VERSION ""

NS_ :

BS_:

BU_: ADTF
VAL_TABLE_ IEBM_State 15 "IEBM_STATE_ERROR" 2 "IEBM_STATE_EMERGENCY_BRAKING" 1 "IEBM_STATE_UPDATING" 0 "IEBM_STATE_STANDBY" ;
VAL_TABLE_ obst_types_to_be_considered 7 "THAS_ALL_OBSTACLES" 6 "THAS_DYNAMIC_AND_PEDESTRIANS" 5 "THAS_ONLY_PEDESTRIANS" 4 "THAS_ONLY_PEDESTRIANS" 3 "THAS_STATIC_AND_DYNAMIC," 2 "THAS_ONLY_DYNAMIC" 1 "THAS_ONLY_STATIC" 0 "default" ;

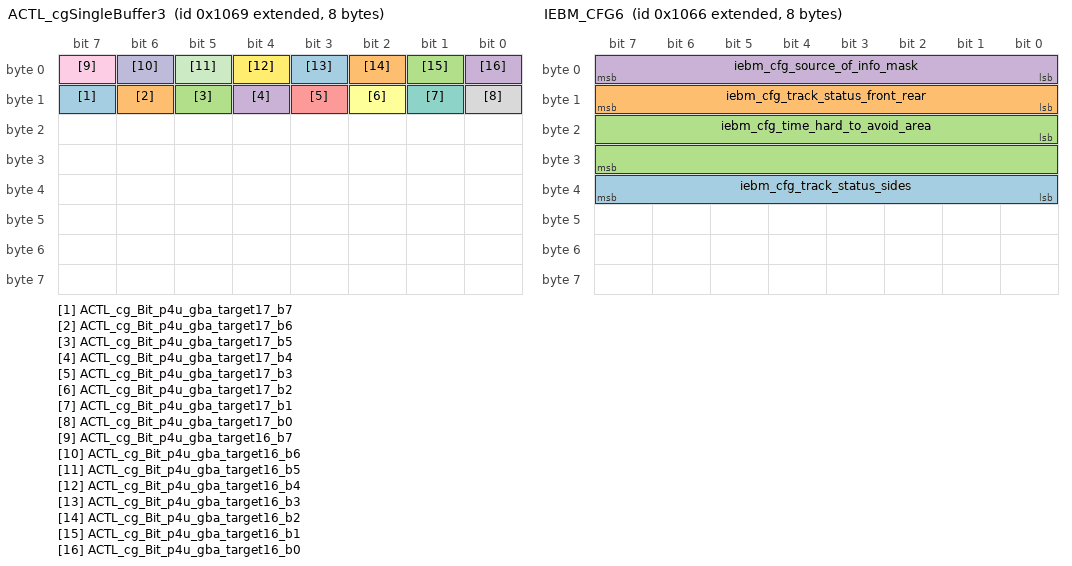
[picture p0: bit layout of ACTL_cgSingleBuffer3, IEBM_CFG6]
BO_ 2147487849 ACTL_cgSingleBuffer3: 8 ADTF
 SG_ ACTL_cg_Bit_p4u_gba_target17_b7 : 15|1@1+ (1,0) [0|0] "" Vector__XXX
 SG_ ACTL_cg_Bit_p4u_gba_target17_b6 : 14|1@1+ (1,0) [0|0] "" Vector__XXX
 SG_ ACTL_cg_Bit_p4u_gba_target17_b5 : 13|1@1+ (1,0) [0|0] "" Vector__XXX
 SG_ ACTL_cg_Bit_p4u_gba_target17_b4 : 12|1@1+ (1,0) [0|0] "" Vector__XXX
 SG_ ACTL_cg_Bit_p4u_gba_target17_b3 : 11|1@1+ (1,0) [0|0] "" Vector__XXX
 SG_ ACTL_cg_Bit_p4u_gba_target17_b2 : 10|1@1+ (1,0) [0|0] "" Vector__XXX
 SG_ ACTL_cg_Bit_p4u_gba_target17_b1 : 9|1@1+ (1,0) [0|0] "" Vector__XXX
 SG_ ACTL_cg_Bit_p4u_gba_target17_b0 : 8|1@1+ (1,0) [0|0] "" Vector__XXX
 SG_ ACTL_cg_Bit_p4u_gba_target16_b7 : 7|1@1+ (1,0) [0|0] "" Vector__XXX
 SG_ ACTL_cg_Bit_p4u_gba_target16_b6 : 6|1@1+ (1,0) [0|0] "" Vector__XXX
 SG_ ACTL_cg_Bit_p4u_gba_target16_b5 : 5|1@1+ (1,0) [0|0] "" Vector__XXX
 SG_ ACTL_cg_Bit_p4u_gba_target16_b4 : 4|1@1+ (1,0) [0|0] "" Vector__XXX
 SG_ ACTL_cg_Bit_p4u_gba_target16_b3 : 3|1@1+ (1,0) [0|0] "" Vector__XXX
 SG_ ACTL_cg_Bit_p4u_gba_target16_b2 : 2|1@1+ (1,0) [0|0] "" Vector__XXX
 SG_ ACTL_cg_Bit_p4u_gba_target16_b1 : 1|1@1+ (1,0) [0|0] "" Vector__XXX
 SG_ ACTL_cg_Bit_p4u_gba_target16_b0 : 0|1@1+ (1,0) [0|0] "" Vector__XXX

BO_ 2147487848 ACTL_cgSingleBuffer2: 8 ADTF
 SG_ ACTL_cg_Bit_p4u_gba_target15_b7 : 63|1@1+ (1,0) [0|0] "" Vector__XXX
 SG_ ACTL_cg_Bit_p4u_gba_target15_b6 : 62|1@1+ (1,0) [0|0] "" Vector__XXX
 SG_ ACTL_cg_Bit_p4u_gba_target15_b5 : 61|1@1+ (1,0) [0|0] "" Vector__XXX
 SG_ ACTL_cg_Bit_p4u_gba_target15_b4 : 60|1@1+ (1,0) [0|0] "" Vector__XXX
 SG_ ACTL_cg_Bit_p4u_gba_target15_b3 : 59|1@1+ (1,0) [0|0] "" Vector__XXX
 SG_ ACTL_cg_Bit_p4u_gba_target15_b2 : 58|1@1+ (1,0) [0|0] "" Vector__XXX
 SG_ ACTL_cg_Bit_p4u_gba_target15_b1 : 57|1@1+ (1,0) [0|0] "" Vector__XXX
 SG_ ACTL_cg_Bit_p4u_gba_target15_b0 : 56|1@1+ (1,0) [0|0] "" Vector__XXX
 SG_ ACTL_cg_Bit_p4u_gba_target14_b7 : 55|1@1+ (1,0) [0|0] "" Vector__XXX
 SG_ ACTL_cg_Bit_p4u_gba_target14_b6 : 54|1@1+ (1,0) [0|0] "" Vector__XXX
 SG_ ACTL_cg_Bit_p4u_gba_target14_b5 : 53|1@1+ (1,0) [0|0] "" Vector__XXX
 SG_ ACTL_cg_Bit_p4u_gba_target14_b4 : 52|1@1+ (1,0) [0|0] "" Vector__XXX
 SG_ ACTL_cg_Bit_p4u_gba_target14_b3 : 51|1@1+ (1,0) [0|0] "" Vector__XXX
 SG_ ACTL_cg_Bit_p4u_gba_target14_b2 : 50|1@1+ (1,0) [0|0] "" Vector__XXX
 SG_ ACTL_cg_Bit_p4u_gba_target14_b1 : 49|1@1+ (1,0) [0|0] "" Vector__XXX
 SG_ ACTL_cg_Bit_p4u_gba_target14_b0 : 48|1@1+ (1,0) [0|0] "" Vector__XXX
 SG_ ACTL_cg_Bit_p4u_gba_target13_b7 : 47|1@1+ (1,0) [0|0] "" Vector__XXX
 SG_ ACTL_cg_Bit_p4u_gba_target13_b6 : 46|1@1+ (1,0) [0|0] "" Vector__XXX
 SG_ ACTL_cg_Bit_p4u_gba_target13_b5 : 45|1@1+ (1,0) [0|0] "" Vector__XXX
 SG_ ACTL_cg_Bit_p4u_gba_target13_b4 : 44|1@1+ (1,0) [0|0] "" Vector__XXX
 SG_ ACTL_cg_Bit_p4u_gba_target13_b3 : 43|1@1+ (1,0) [0|0] "" Vector__XXX
 SG_ ACTL_cg_Bit_p4u_gba_target13_b2 : 42|1@1+ (1,0) [0|0] "" Vector__XXX
 SG_ ACTL_cg_Bit_p4u_gba_target13_b1 : 41|1@1+ (1,0) [0|0] "" Vector__XXX
 SG_ ACTL_cg_Bit_p4u_gba_target13_b0 : 40|1@1+ (1,0) [0|0] "" Vector__XXX
 SG_ ACTL_cg_Bit_p4u_gba_target12_b7 : 39|1@1+ (1,0) [0|0] "" Vector__XXX
 SG_ ACTL_cg_Bit_p4u_gba_target12_b6 : 38|1@1+ (1,0) [0|0] "" Vector__XXX
 SG_ ACTL_cg_Bit_p4u_gba_target12_b5 : 37|1@1+ (1,0) [0|0] "" Vector__XXX
 SG_ ACTL_cg_Bit_p4u_gba_target12_b4 : 36|1@1+ (1,0) [0|0] "" Vector__XXX
 SG_ ACTL_cg_Bit_p4u_gba_target12_b3 : 35|1@1+ (1,0) [0|0] "" Vector__XXX
 SG_ ACTL_cg_Bit_p4u_gba_target12_b2 : 34|1@1+ (1,0) [0|0] "" Vector__XXX
 SG_ ACTL_cg_Bit_p4u_gba_target12_b1 : 33|1@1+ (1,0) [0|0] "" Vector__XXX
 SG_ ACTL_cg_Bit_p4u_gba_target12_b0 : 32|1@1+ (1,0) [0|0] "" Vector__XXX
 SG_ ACTL_cg_Bit_p4u_gba_target11_b7 : 31|1@1+ (1,0) [0|0] "" Vector__XXX
 SG_ ACTL_cg_Bit_p4u_gba_target11_b6 : 30|1@1+ (1,0) [0|0] "" Vector__XXX
 SG_ ACTL_cg_Bit_p4u_gba_target11_b5 : 29|1@1+ (1,0) [0|0] "" Vector__XXX
 SG_ ACTL_cg_Bit_p4u_gba_target11_b4 : 28|1@1+ (1,0) [0|0] "" Vector__XXX
 SG_ ACTL_cg_Bit_p4u_gba_target11_b3 : 27|1@1+ (1,0) [0|0] "" Vector__XXX
 SG_ ACTL_cg_Bit_p4u_gba_target11_b2 : 26|1@1+ (1,0) [0|1] "" Vector__XXX
 SG_ ACTL_cg_Bit_p4u_gba_target11_b1 : 25|1@1+ (1,0) [0|0] "" Vector__XXX
 SG_ ACTL_cg_Bit_p4u_gba_target11_b0 : 24|1@1+ (1,0) [0|0] "" Vector__XXX
 SG_ ACTL_cg_Bit_p4u_gba_target10_b7 : 23|1@1+ (1,0) [0|0] "" Vector__XXX
 SG_ ACTL_cg_Bit_p4u_gba_target10_b6 : 22|1@1+ (1,0) [0|0] "" Vector__XXX
 SG_ ACTL_cg_Bit_p4u_gba_target10_b5 : 21|1@1+ (1,0) [0|0] "" Vector__XXX
 SG_ ACTL_cg_Bit_p4u_gba_target10_b4 : 20|1@1+ (1,0) [0|0] "" Vector__XXX
 SG_ ACTL_cg_Bit_p4u_gba_target10_b3 : 19|1@1+ (1,0) [0|0] "" Vector__XXX
 SG_ ACTL_cg_Bit_p4u_gba_target10_b2 : 18|1@1+ (1,0) [0|0] "" Vector__XXX
 SG_ ACTL_cg_Bit_p4u_gba_target10_b1 : 17|1@1+ (1,0) [0|0] "" Vector__XXX
 SG_ ACTL_cg_Bit_p4u_gba_target10_b0 : 16|1@1+ (1,0) [0|0] "" Vector__XXX
 SG_ ACTL_cg_Bit_p4u_gba_target9_b7 : 15|1@1+ (1,0) [0|0] "" Vector__XXX
 SG_ ACTL_cg_Bit_p4u_gba_target9_b6 : 14|1@1+ (1,0) [0|0] "" Vector__XXX
 SG_ ACTL_cg_Bit_p4u_gba_target9_b5 : 13|1@1+ (1,0) [0|0] "" Vector__XXX
 SG_ ACTL_cg_Bit_p4u_gba_target9_b4 : 12|1@1+ (1,0) [0|0] "" Vector__XXX
 SG_ ACTL_cg_Bit_p4u_gba_target9_b3 : 11|1@1+ (1,0) [0|0] "" Vector__XXX
 SG_ ACTL_cg_Bit_p4u_gba_target9_b2 : 10|1@1+ (1,0) [0|0] "" Vector__XXX
 SG_ ACTL_cg_Bit_p4u_gba_target9_b1 : 9|1@1+ (1,0) [0|0] "" Vector__XXX
 SG_ ACTL_cg_Bit_p4u_gba_target9_b0 : 8|1@1+ (1,0) [0|0] "" Vector__XXX
 SG_ ACTL_cg_Bit_p4u_gba_target8_b7 : 7|1@1+ (1,0) [0|0] "" Vector__XXX
 SG_ ACTL_cg_Bit_p4u_gba_target8_b6 : 6|1@1+ (1,0) [0|0] "" Vector__XXX
 SG_ ACTL_cg_Bit_p4u_gba_target8_b5 : 5|1@1+ (1,0) [0|0] "" Vector__XXX
 SG_ ACTL_cg_Bit_p4u_gba_target8_b4 : 4|1@1+ (1,0) [0|0] "" Vector__XXX
 SG_ ACTL_cg_Bit_p4u_gba_target8_b3 : 3|1@1+ (1,0) [0|0] "" Vector__XXX
 SG_ ACTL_cg_Bit_p4u_gba_target8_b2 : 2|1@1+ (1,0) [0|0] "" Vector__XXX
 SG_ ACTL_cg_Bit_p4u_gba_target8_b1 : 1|1@1+ (1,0) [0|0] "" Vector__XXX
 SG_ ACTL_cg_Bit_p4u_gba_target8_b0 : 0|1@1+ (1,0) [0|0] "" Vector__XXX

BO_ 2147487847 ACTL_cgSingleBuffer1: 8 ADTF
 SG_ ACTL_cg_Bit_p4u_gba_target7_b7 : 63|1@1+ (1,0) [0|0] "" Vector__XXX
 SG_ ACTL_cg_Bit_p4u_gba_target7_b6 : 62|1@1+ (1,0) [0|0] "" Vector__XXX
 SG_ ACTL_cg_Bit_p4u_gba_target7_b5 : 61|1@1+ (1,0) [0|0] "" Vector__XXX
 SG_ ACTL_cg_Bit_p4u_gba_target7_b4 : 60|1@1+ (1,0) [0|0] "" Vector__XXX
 SG_ ACTL_cg_Bit_p4u_gba_target7_b3 : 59|1@1+ (1,0) [0|0] "" Vector__XXX
 SG_ ACTL_cg_Bit_p4u_gba_target7_b2 : 58|1@1+ (1,0) [0|0] "" Vector__XXX
 SG_ ACTL_cg_Bit_p4u_gba_target7_b1 : 57|1@1+ (1,0) [0|0] "" Vector__XXX
 SG_ ACTL_cg_Bit_p4u_gba_target7_b0 : 56|1@1+ (1,0) [0|0] "" Vector__XXX
 SG_ ACTL_cg_Bit_p4u_gba_target6_b7 : 55|1@1+ (1,0) [0|0] "" Vector__XXX
 SG_ ACTL_cg_Bit_p4u_gba_target6_b6 : 54|1@1+ (1,0) [0|0] "" Vector__XXX
 SG_ ACTL_cg_Bit_p4u_gba_target6_b5 : 53|1@1+ (1,0) [0|0] "" Vector__XXX
 SG_ ACTL_cg_Bit_p4u_gba_target6_b4 : 52|1@1+ (1,0) [0|0] "" Vector__XXX
 SG_ ACTL_cg_Bit_p4u_gba_target6_b3 : 51|1@1+ (1,0) [0|0] "" Vector__XXX
 SG_ ACTL_cg_Bit_p4u_gba_target6_b2 : 50|1@1+ (1,0) [0|0] "" Vector__XXX
 SG_ ACTL_cg_Bit_p4u_gba_target6_b1 : 49|1@1+ (1,0) [0|0] "" Vector__XXX
 SG_ ACTL_cg_Bit_p4u_gba_target6_b0 : 48|1@1+ (1,0) [0|0] "" Vector__XXX
 SG_ ACTL_cg_Bit_p4u_gba_target5_b7 : 47|1@1+ (1,0) [0|0] "" Vector__XXX
 SG_ ACTL_cg_Bit_p4u_gba_target5_b6 : 46|1@1+ (1,0) [0|0] "" Vector__XXX
 SG_ ACTL_cg_Bit_p4u_gba_target5_b5 : 45|1@1+ (1,0) [0|0] "" Vector__XXX
 SG_ ACTL_cg_Bit_p4u_gba_target5_b4 : 44|1@1+ (1,0) [0|0] "" Vector__XXX
 SG_ ACTL_cg_Bit_p4u_gba_target5_b3 : 43|1@1+ (1,0) [0|0] "" Vector__XXX
 SG_ ACTL_cg_Bit_p4u_gba_target5_b2 : 42|1@1+ (1,0) [0|0] "" Vector__XXX
 SG_ ACTL_cg_Bit_p4u_gba_target5_b1 : 41|1@1+ (1,0) [0|0] "" Vector__XXX
 SG_ ACTL_cg_Bit_p4u_gba_target5_b0 : 40|1@1+ (1,0) [0|0] "" Vector__XXX
 SG_ ACTL_cg_Bit_p4u_gba_target4_b7 : 39|1@1+ (1,0) [0|0] "" Vector__XXX
 SG_ ACTL_cg_Bit_p4u_gba_target4_b6 : 38|1@1+ (1,0) [0|0] "" Vector__XXX
 SG_ ACTL_cg_Bit_p4u_gba_target4_b5 : 37|1@1+ (1,0) [0|0] "" Vector__XXX
 SG_ ACTL_cg_Bit_p4u_gba_target4_b4 : 36|1@1+ (1,0) [0|0] "" Vector__XXX
 SG_ ACTL_cg_Bit_p4u_gba_target4_b3 : 35|1@1+ (1,0) [0|0] "" Vector__XXX
 SG_ ACTL_cg_Bit_p4u_gba_target4_b2 : 34|1@1+ (1,0) [0|0] "" Vector__XXX
 SG_ ACTL_cg_Bit_p4u_gba_target4_b1 : 33|1@1+ (1,0) [0|0] "" Vector__XXX
 SG_ ACTL_cg_Bit_p4u_gba_target4_b0 : 32|1@1+ (1,0) [0|0] "" Vector__XXX
 SG_ ACTL_cg_Bit_p4u_gba_target3_b7 : 31|1@1+ (1,0) [0|0] "" Vector__XXX
 SG_ ACTL_cg_Bit_p4u_gba_target3_b6 : 30|1@1+ (1,0) [0|0] "" Vector__XXX
 SG_ ACTL_cg_Bit_p4u_gba_target3_b5 : 29|1@1+ (1,0) [0|0] "" Vector__XXX
 SG_ ACTL_cg_Bit_p4u_gba_target3_b4 : 28|1@1+ (1,0) [0|0] "" Vector__XXX
 SG_ ACTL_cg_Bit_p4u_gba_target3_b3 : 27|1@1+ (1,0) [0|0] "" Vector__XXX
 SG_ ACTL_cg_Bit_p4u_gba_target3_b2 : 26|1@1+ (1,0) [0|0] "" Vector__XXX
 SG_ ACTL_cg_Bit_p4u_gba_target3_b1 : 25|1@1+ (1,0) [0|0] "" Vector__XXX
 SG_ ACTL_cg_Bit_p4u_gba_target3_b0 : 24|1@1+ (1,0) [0|0] "" Vector__XXX
 SG_ ACTL_cg_Bit_p4u_gba_target2_b7 : 23|1@1+ (1,0) [0|0] "" Vector__XXX
 SG_ ACTL_cg_Bit_p4u_gba_target2_b6 : 22|1@1+ (1,0) [0|0] "" Vector__XXX
 SG_ ACTL_cg_Bit_p4u_gba_target2_b5 : 21|1@1+ (1,0) [0|0] "" Vector__XXX
 SG_ ACTL_cg_Bit_p4u_gba_target2_b4 : 20|1@1+ (1,0) [0|0] "" Vector__XXX
 SG_ ACTL_cg_Bit_p4u_gba_target2_b3 : 19|1@1+ (1,0) [0|0] "" Vector__XXX
 SG_ ACTL_cg_Bit_p4u_gba_target2_b2 : 18|1@1+ (1,0) [0|0] "" Vector__XXX
 SG_ ACTL_cg_Bit_p4u_gba_target2_b1 : 17|1@1+ (1,0) [0|0] "" Vector__XXX
 SG_ ACTL_cg_Bit_p4u_gba_target2_b0 : 16|1@1+ (1,0) [0|0] "" Vector__XXX
 SG_ ACTL_cg_Bit_p4u_gba_target1_b7 : 15|1@1+ (1,0) [0|0] "" Vector__XXX
 SG_ ACTL_cg_Bit_p4u_gba_target1_b6 : 14|1@1+ (1,0) [0|0] "" Vector__XXX
 SG_ ACTL_cg_Bit_p4u_gba_target1_b5 : 13|1@1+ (1,0) [0|0] "" Vector__XXX
 SG_ ACTL_cg_Bit_p4u_gba_target1_b4 : 12|1@1+ (1,0) [0|0] "" Vector__XXX
 SG_ ACTL_cg_Bit_p4u_gba_target1_b3 : 11|1@1+ (1,0) [0|0] "" Vector__XXX
 SG_ ACTL_cg_Bit_p4u_gba_target1_b2 : 10|1@1+ (1,0) [0|0] "" Vector__XXX
 SG_ ACTL_cg_Bit_p4u_gba_target1_b1 : 9|1@1+ (1,0) [0|0] "" Vector__XXX
 SG_ ACTL_cg_Bit_p4u_gba_target1_b0 : 8|1@1+ (1,0) [0|0] "" Vector__XXX
 SG_ ACTL_cg_Bit_p4u_gba_target_b7 : 7|1@1+ (1,0) [0|0] "" Vector__XXX
 SG_ ACTL_cg_Bit_p4u_gba_target_b6 : 6|1@1+ (1,0) [0|0] "" Vector__XXX
 SG_ ACTL_cg_Bit_p4u_gba_target_b5 : 5|1@1+ (1,0) [0|0] "" Vector__XXX
 SG_ ACTL_cg_Bit_p4u_gba_target_b4 : 4|1@1+ (1,0) [0|0] "" Vector__XXX
 SG_ ACTL_cg_Bit_p4u_gba_target_b3 : 3|1@1+ (1,0) [0|0] "" Vector__XXX
 SG_ ACTL_cg_Bit_p4u_gba_target_b2 : 2|1@1+ (1,0) [0|0] "" Vector__XXX
 SG_ ACTL_cg_Bit_p4u_gba_target_b1 : 1|1@1+ (1,0) [0|0] "" Vector__XXX
 SG_ ACTL_cg_Bit_p4u_gba_target_b0 : 0|1@1+ (1,0) [0|0] "" Vector__XXX

BO_ 2147487846 IEBM_CFG6: 8 ADTF
 SG_ iebm_cfg_track_status_sides : 32|8@1+ (1,0) [0|0] "" Vector__XXX
 SG_ iebm_cfg_track_status_front_rear : 8|8@1+ (1,0) [0|0] "" Vector__XXX
 SG_ iebm_cfg_time_hard_to_avoid_area : 16|16@1+ (1,0) [0|0] "" Vector__XXX
 SG_ iebm_cfg_source_of_info_mask : 0|8@1+ (1,0) [0|0] "" Vector__XXX

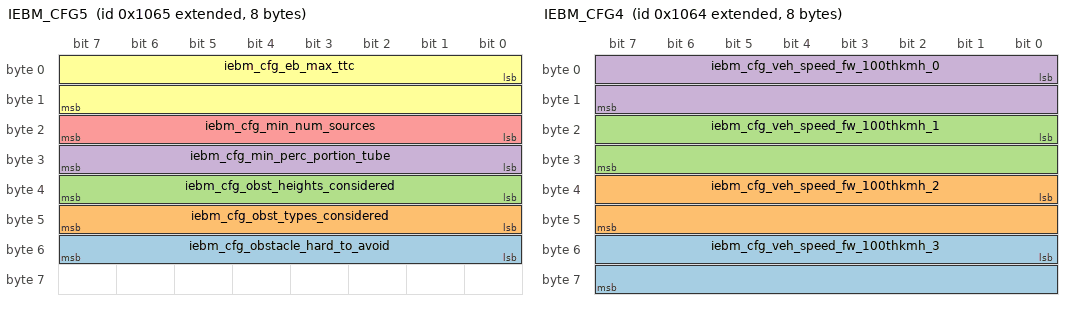
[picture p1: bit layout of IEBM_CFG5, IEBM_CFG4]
BO_ 2147487845 IEBM_CFG5: 8 ADTF
 SG_ iebm_cfg_obstacle_hard_to_avoid : 48|8@1+ (1,0) [0|0] "" Vector__XXX
 SG_ iebm_cfg_obst_types_considered : 40|8@1+ (1,0) [0|0] "" Vector__XXX
 SG_ iebm_cfg_obst_heights_considered : 32|8@1+ (1,0) [0|0] "" Vector__XXX
 SG_ iebm_cfg_min_perc_portion_tube : 24|8@1+ (1,0) [0|0] "" Vector__XXX
 SG_ iebm_cfg_min_num_sources : 16|8@1+ (1,0) [0|0] "" Vector__XXX
 SG_ iebm_cfg_eb_max_ttc : 0|16@1+ (1,0) [0|0] "" Vector__XXX

BO_ 2147487844 IEBM_CFG4: 8 ADTF
 SG_ iebm_cfg_veh_speed_fw_100thkmh_3 : 48|16@1+ (1,0) [0|0] "" Vector__XXX
 SG_ iebm_cfg_veh_speed_fw_100thkmh_2 : 32|16@1+ (1,0) [0|0] "" Vector__XXX
 SG_ iebm_cfg_veh_speed_fw_100thkmh_1 : 16|16@1+ (1,0) [0|0] "" Vector__XXX
 SG_ iebm_cfg_veh_speed_fw_100thkmh_0 : 0|16@1+ (1,0) [0|0] "" Vector__XXX

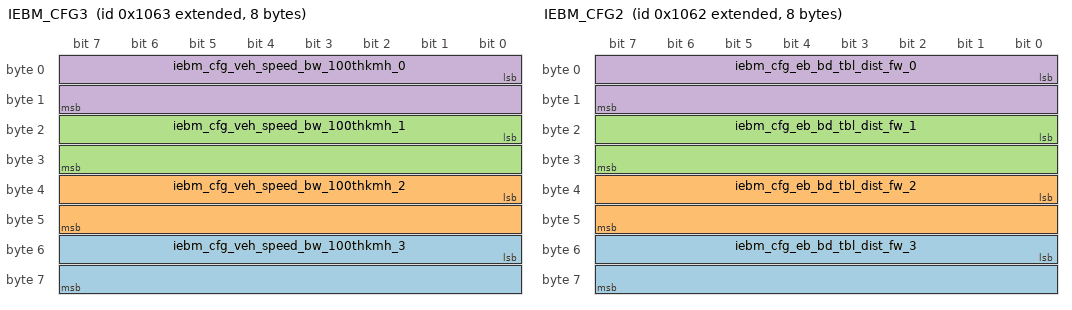
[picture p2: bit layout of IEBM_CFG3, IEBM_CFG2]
BO_ 2147487843 IEBM_CFG3: 8 ADTF
 SG_ iebm_cfg_veh_speed_bw_100thkmh_3 : 48|16@1+ (1,0) [0|0] "" Vector__XXX
 SG_ iebm_cfg_veh_speed_bw_100thkmh_2 : 32|16@1+ (1,0) [0|0] "" Vector__XXX
 SG_ iebm_cfg_veh_speed_bw_100thkmh_1 : 16|16@1+ (1,0) [0|0] "" Vector__XXX
 SG_ iebm_cfg_veh_speed_bw_100thkmh_0 : 0|16@1+ (1,0) [0|0] "" Vector__XXX

BO_ 2147487842 IEBM_CFG2: 8 ADTF
 SG_ iebm_cfg_eb_bd_tbl_dist_fw_3 : 48|16@1- (1,0) [0|0] "" Vector__XXX
 SG_ iebm_cfg_eb_bd_tbl_dist_fw_2 : 32|16@1- (1,0) [0|0] "" Vector__XXX
 SG_ iebm_cfg_eb_bd_tbl_dist_fw_1 : 16|16@1- (1,0) [0|0] "" Vector__XXX
 SG_ iebm_cfg_eb_bd_tbl_dist_fw_0 : 0|16@1- (1,0) [0|0] "" Vector__XXX

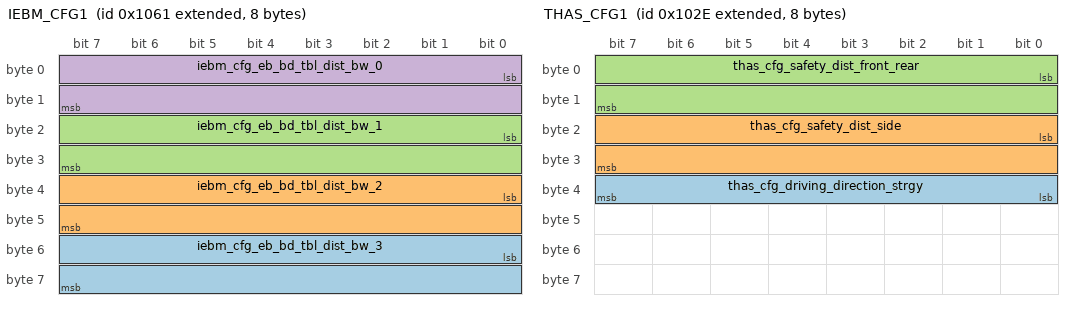
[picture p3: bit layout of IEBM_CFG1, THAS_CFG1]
BO_ 2147487841 IEBM_CFG1: 8 ADTF
 SG_ iebm_cfg_eb_bd_tbl_dist_bw_3 : 48|16@1- (1,0) [0|0] "" Vector__XXX
 SG_ iebm_cfg_eb_bd_tbl_dist_bw_2 : 32|16@1- (1,0) [0|0] "" Vector__XXX
 SG_ iebm_cfg_eb_bd_tbl_dist_bw_1 : 16|16@1- (1,0) [0|0] "" Vector__XXX
 SG_ iebm_cfg_eb_bd_tbl_dist_bw_0 : 0|16@1- (1,0) [0|0] "" Vector__XXX

BO_ 2147487790 THAS_CFG1: 8 ADTF
 SG_ thas_cfg_driving_direction_strgy : 32|8@1- (1,0) [0|0] "" Vector__XXX
 SG_ thas_cfg_safety_dist_side : 16|16@1+ (1,0) [0|0] "" Vector__XXX
 SG_ thas_cfg_safety_dist_front_rear : 0|16@1+ (1,0) [0|0] "" Vector__XXX

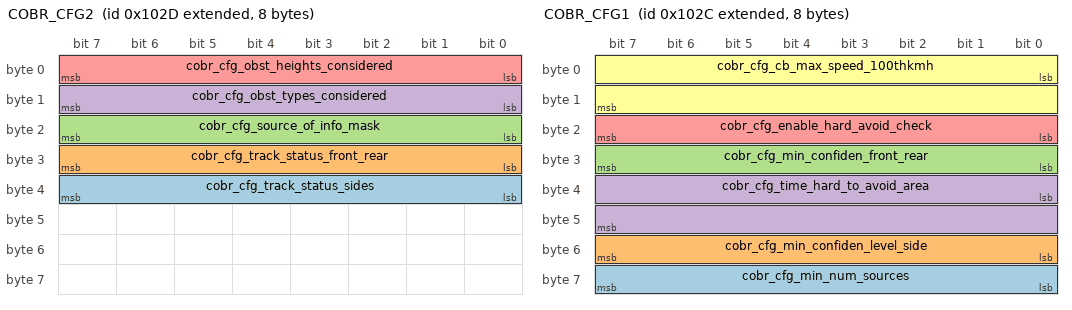
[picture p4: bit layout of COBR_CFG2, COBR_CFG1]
BO_ 2147487789 COBR_CFG2: 8 ADTF
 SG_ cobr_cfg_track_status_sides : 32|8@1+ (1,0) [0|0] "" Vector__XXX
 SG_ cobr_cfg_track_status_front_rear : 24|8@1+ (1,0) [0|0] "" Vector__XXX
 SG_ cobr_cfg_source_of_info_mask : 16|8@1+ (1,0) [0|0] "" Vector__XXX
 SG_ cobr_cfg_obst_types_considered : 8|8@1+ (1,0) [0|0] "" Vector__XXX
 SG_ cobr_cfg_obst_heights_considered : 0|8@1+ (1,0) [0|0] "" Vector__XXX

BO_ 2147487788 COBR_CFG1: 8 ADTF
 SG_ cobr_cfg_min_num_sources : 56|8@1+ (1,0) [0|0] "" Vector__XXX
 SG_ cobr_cfg_min_confiden_level_side : 48|8@1+ (1,0) [0|0] "" Vector__XXX
 SG_ cobr_cfg_min_confiden_front_rear : 24|8@1+ (1,0) [0|0] "" Vector__XXX
 SG_ cobr_cfg_time_hard_to_avoid_area : 32|16@1+ (1,0) [0|0] "" Vector__XXX
 SG_ cobr_cfg_enable_hard_avoid_check : 16|8@1+ (1,0) [0|0] "" Vector__XXX
 SG_ cobr_cfg_cb_max_speed_100thkmh : 0|16@1+ (1,0) [0|0] "" Vector__XXX

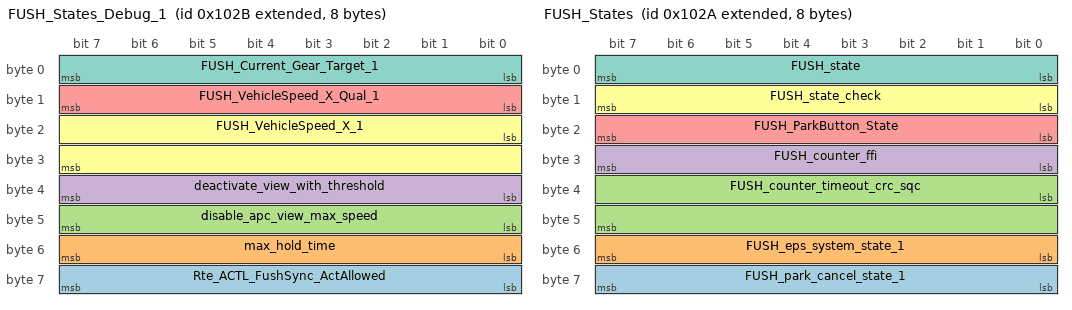
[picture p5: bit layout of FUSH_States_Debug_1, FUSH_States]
BO_ 2147487787 FUSH_States_Debug_1: 8 ADTF
 SG_ Rte_ACTL_FushSync_ActAllowed : 56|8@1+ (1,0) [0|0] "" Vector__XXX
 SG_ max_hold_time : 48|8@1+ (1,0) [0|0] "" Vector__XXX
 SG_ disable_apc_view_max_speed : 40|8@1+ (1,0) [0|0] "" Vector__XXX
 SG_ deactivate_view_with_threshold : 32|8@1+ (1,0) [0|0] "" Vector__XXX
 SG_ FUSH_VehicleSpeed_X_Qual_1 : 8|8@1+ (1,0) [0|0] "" Vector__XXX
 SG_ FUSH_VehicleSpeed_X_1 : 16|16@1+ (1,0) [0|0] "" Vector__XXX
 SG_ FUSH_Current_Gear_Target_1 : 0|8@1+ (1,0) [0|0] "" Vector__XXX

BO_ 2147487786 FUSH_States: 8 ADTF
 SG_ FUSH_park_cancel_state_1 : 56|8@1+ (1,0) [0|0] "" Vector__XXX
 SG_ FUSH_eps_system_state_1 : 48|8@1+ (1,0) [0|0] "" Vector__XXX
 SG_ FUSH_counter_timeout_crc_sqc : 32|16@1+ (1,0) [0|0] "" Vector__XXX
 SG_ FUSH_counter_ffi : 24|8@1+ (1,0) [0|0] "" Vector__XXX
 SG_ FUSH_ParkButton_State : 16|8@1- (1,0) [0|0] "" Vector__XXX
 SG_ FUSH_state_check : 8|8@1- (1,0) [0|0] "" Vector__XXX
 SG_ FUSH_state : 0|8@1- (1,0) [0|0] "" Vector__XXX

BO_ 2147487785 ACTL_TOP_AC2: 4 ADTF
 SG_ ACTL_TOP_AC_A_RD_DTH : 16|16@1- (1,0) [-32768|32767] "" Vector__XXX
 SG_ ACTL_TOP_AC_A_RD_DTC : 0|16@1- (1,0) [-32768|32767] "" Vector__XXX

BO_ 2147487784 ACTL_TOP_AC1: 8 ADTF
 SG_ ACTL_TOP_AC_A_RD_JUMP_DTH : 32|32@1- (1,0) [-2147483648|2147483647] "" Vector__XXX
 SG_ ACTL_TOP_AC_A_RD_JUMP_DTC : 0|32@1- (1,0) [-2147483648|2147483647] "" Vector__XXX

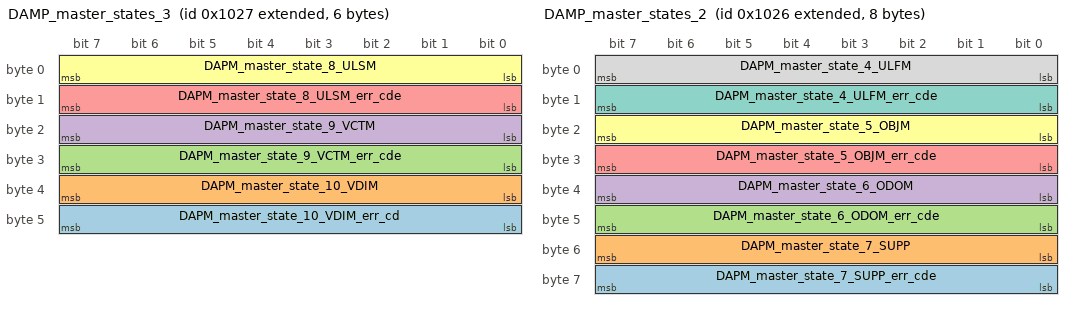
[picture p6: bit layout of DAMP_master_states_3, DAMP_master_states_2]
BO_ 2147487783 DAMP_master_states_3: 6 ADTF
 SG_ DAPM_master_state_10_VDIM_err_cd : 40|8@1- (1,0) [0|0] "" Vector__XXX
 SG_ DAPM_master_state_10_VDIM : 32|8@1- (1,0) [0|0] "" Vector__XXX
 SG_ DAPM_master_state_9_VCTM_err_cde : 24|8@1- (1,0) [0|0] "" Vector__XXX
 SG_ DAPM_master_state_9_VCTM : 16|8@1- (1,0) [0|0] "" Vector__XXX
 SG_ DAPM_master_state_8_ULSM_err_cde : 8|8@1- (1,0) [0|0] "" Vector__XXX
 SG_ DAPM_master_state_8_ULSM : 0|8@1- (1,0) [0|0] "" Vector__XXX

BO_ 2147487782 DAMP_master_states_2: 8 ADTF
 SG_ DAPM_master_state_7_SUPP_err_cde : 56|8@1- (1,0) [0|0] "" Vector__XXX
 SG_ DAPM_master_state_7_SUPP : 48|8@1- (1,0) [0|0] "" Vector__XXX
 SG_ DAPM_master_state_6_ODOM_err_cde : 40|8@1- (1,0) [0|0] "" Vector__XXX
 SG_ DAPM_master_state_6_ODOM : 32|8@1- (1,0) [0|0] "" Vector__XXX
 SG_ DAPM_master_state_5_OBJM_err_cde : 24|8@1- (1,0) [0|0] "" Vector__XXX
 SG_ DAPM_master_state_5_OBJM : 16|8@1- (1,0) [0|0] "" Vector__XXX
 SG_ DAPM_master_state_4_ULFM_err_cde : 8|8@1- (1,0) [0|0] "" Vector__XXX
 SG_ DAPM_master_state_4_ULFM : 0|8@1- (1,0) [0|0] "" Vector__XXX

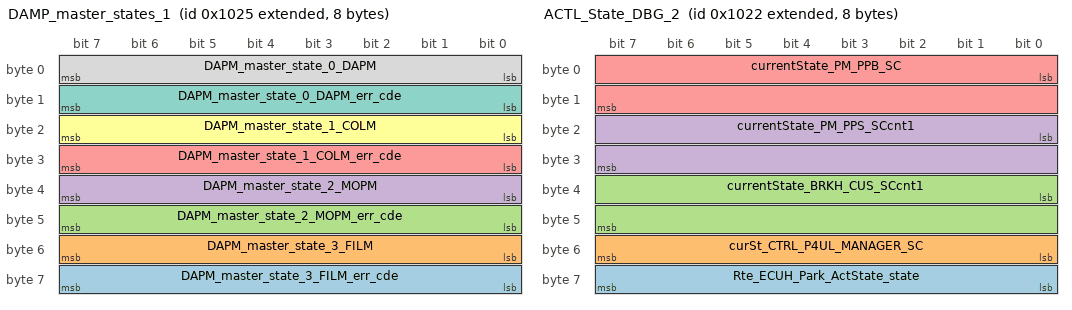
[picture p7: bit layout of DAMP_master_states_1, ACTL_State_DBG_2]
BO_ 2147487781 DAMP_master_states_1: 8 ADTF
 SG_ DAPM_master_state_3_FILM_err_cde : 56|8@1- (1,0) [0|0] "" Vector__XXX
 SG_ DAPM_master_state_3_FILM : 48|8@1- (1,0) [0|0] "" Vector__XXX
 SG_ DAPM_master_state_2_MOPM_err_cde : 40|8@1- (1,0) [0|0] "" Vector__XXX
 SG_ DAPM_master_state_2_MOPM : 32|8@1- (1,0) [0|0] "" Vector__XXX
 SG_ DAPM_master_state_1_COLM_err_cde : 24|8@1- (1,0) [0|0] "" Vector__XXX
 SG_ DAPM_master_state_1_COLM : 16|8@1- (1,0) [0|0] "" Vector__XXX
 SG_ DAPM_master_state_0_DAPM_err_cde : 8|8@1- (1,0) [0|0] "" Vector__XXX
 SG_ DAPM_master_state_0_DAPM : 0|8@1- (1,0) [0|0] "" Vector__XXX

BO_ 2147487778 ACTL_State_DBG_2: 8 ADTF
 SG_ Rte_ECUH_Park_ActState_state : 56|8@1+ (1,0) [0|0] "" Vector__XXX
 SG_ curSt_CTRL_P4UL_MANAGER_SC : 48|8@1+ (1,0) [0|0] "" Vector__XXX
 SG_ currentState_BRKH_CUS_SCcnt1 : 32|16@1- (1,0) [0|0] "" Vector__XXX
 SG_ currentState_PM_PPS_SCcnt1 : 16|16@1+ (1,0) [0|0] "" Vector__XXX
 SG_ currentState_PM_PPB_SC : 0|16@1+ (1,0) [0|0] "" Vector__XXX

BO_ 2147487779 XCP_COBR_DBG: 4 ADTF
 SG_ XCP_COBR_minDTC : 16|16@1+ (1,0) [0|0] "" Vector__XXX
 SG_ XCP_COBR_State : 0|8@1- (1,0) [0|0] "" Vector__XXX

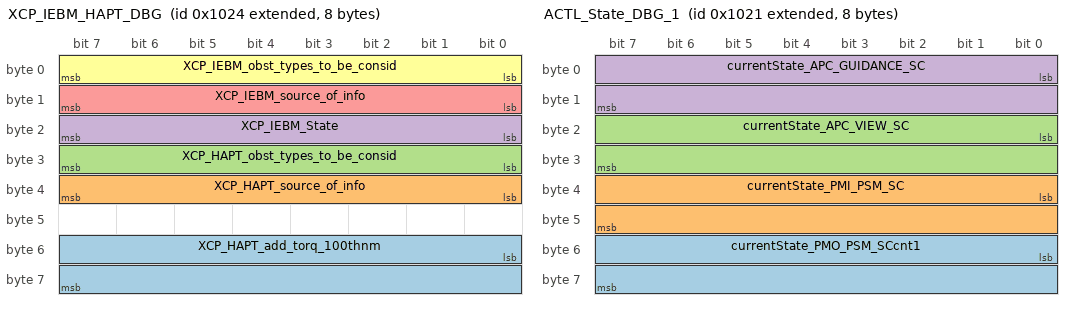
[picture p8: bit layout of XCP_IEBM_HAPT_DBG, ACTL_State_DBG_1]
BO_ 2147487780 XCP_IEBM_HAPT_DBG: 8 ADTF
 SG_ XCP_HAPT_add_torq_100thnm : 48|16@1- (1,0) [0|0] "" Vector__XXX
 SG_ XCP_HAPT_source_of_info : 32|8@1+ (1,0) [0|0] "" Vector__XXX
 SG_ XCP_HAPT_obst_types_to_be_consid : 24|8@1- (1,0) [0|0] "" Vector__XXX
 SG_ XCP_IEBM_State : 16|8@1- (1,0) [0|0] "" Vector__XXX
 SG_ XCP_IEBM_source_of_info : 8|8@1+ (1,0) [0|0] "" Vector__XXX
 SG_ XCP_IEBM_obst_types_to_be_consid : 0|8@1- (1,0) [0|0] "" Vector__XXX

BO_ 2147487777 ACTL_State_DBG_1: 8 ADTF
 SG_ currentState_PMO_PSM_SCcnt1 : 48|16@1+ (1,0) [0|0] "" Vector__XXX
 SG_ currentState_PMI_PSM_SC : 32|16@1+ (1,0) [0|0] "" Vector__XXX
 SG_ currentState_APC_VIEW_SC : 16|16@1- (1,0) [0|0] "" Vector__XXX
 SG_ currentState_APC_GUIDANCE_SC : 0|16@1+ (1,0) [0|0] "" Vector__XXX

BA_DEF_  "BusType" STRING ;
BA_DEF_DEF_  "BusType" "CAN";
VAL_ 2147487786 FUSH_ParkButton_State 1 "True" 0 "False" ;
VAL_ 2147487786 FUSH_state_check 5 "RPA_ACTIVE_DEADMAN_NOK" 4 "RPA_ACTIVE_DEADMAN_OK" 3 "RPA_INACTIVE" 2 "APC" 1 "PARK" 0 "NONE" ;
VAL_ 2147487786 FUSH_state 5 "RPA_ACTIVE_DEADMAN_NOK" 4 "RPA_ACTIVE_DEADMAN_OK" 3 "RPA_INACTIVE" 2 "APC" 1 "PARK" 0 "NONE" ;
VAL_ 2147487780 XCP_HAPT_obst_types_to_be_consid 7 "THAS_ALL_OBSTACLES" 6 "THAS_DYNAMIC_AND_PEDESTRIANS" 5 "THAS_ONLY_PEDESTRIANS" 4 "THAS_ONLY_PEDESTRIANS" 3 "THAS_STATIC_AND_DYNAMIC," 2 "THAS_ONLY_DYNAMIC" 1 "THAS_ONLY_STATIC" 0 "default" ;
VAL_ 2147487780 XCP_IEBM_obst_types_to_be_consid 7 "THAS_ALL_OBSTACLES" 6 "THAS_DYNAMIC_AND_PEDESTRIANS" 5 "THAS_ONLY_PEDESTRIANS" 4 "THAS_ONLY_PEDESTRIANS" 3 "THAS_STATIC_AND_DYNAMIC," 2 "THAS_ONLY_DYNAMIC" 1 "THAS_ONLY_STATIC" 0 "default" ;
